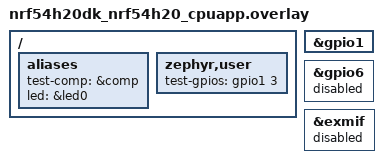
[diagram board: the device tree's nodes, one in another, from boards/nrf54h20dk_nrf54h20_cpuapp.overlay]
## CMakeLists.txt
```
#
# Copyright (c) 2024 Nordic Semiconductor ASA
#
# SPDX-License-Identifier: LicenseRef-Nordic-5-Clause
#

cmake_minimum_required(VERSION 3.20.0)

find_package(Zephyr REQUIRED HINTS $ENV{ZEPHYR_BASE})
if(NOT SYSBUILD)
  message(FATAL_ERROR
    " This is a multi-image application that should be built using sysbuild.\n"
    " Add --sysbuild argument to west build command to prepare all the images."
  )
endif()

project(idle_comp)

target_sources(app PRIVATE src/main.c)
```

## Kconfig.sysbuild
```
#
# Copyright (c) 2024 Nordic Semiconductor ASA
#
# SPDX-License-Identifier: LicenseRef-Nordic-5-Clause
#

choice NETCORE
	default NETCORE_REMOTE_SLEEP_FOREVER

config NETCORE_REMOTE_SLEEP_FOREVER
	bool "Remote sleep forever image"

endchoice

config NETCORE_IMAGE_NAME
	default "remote_sleep_forever" if NETCORE_REMOTE_SLEEP_FOREVER

config NETCORE_IMAGE_PATH
	default "$(ZEPHYR_NRF_MODULE_DIR)/tests/benchmarks/power_consumption/common/remote_sleep_forever" if NETCORE_REMOTE_SLEEP_FOREVER

source "share/sysbuild/Kconfig"
```

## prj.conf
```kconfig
CONFIG_COMPARATOR=y
CONFIG_GPIO=y

CONFIG_PM=y
CONFIG_PM_DEVICE=y
CONFIG_PM_DEVICE_RUNTIME=y
CONFIG_POWEROFF=y
CONFIG_BOOT_BANNER=n
CONFIG_NCS_BOOT_BANNER=n
CONFIG_ASSERT=y

# Enable for debugging purposes only
CONFIG_PRINTK=n
CONFIG_LOG=n
CONFIG_CONSOLE=n
CONFIG_UART_CONSOLE=n
CONFIG_SERIAL=n
```

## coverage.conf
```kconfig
CONFIG_COMPARATOR=y
CONFIG_GPIO=y

CONFIG_PM=y
CONFIG_PM_DEVICE=y
CONFIG_PM_DEVICE_RUNTIME=y
CONFIG_POWEROFF=y

CONFIG_BOOT_BANNER=n
CONFIG_NCS_BOOT_BANNER=n
CONFIG_ASSERT=n
CONFIG_CLOCK_CONTROL=n

CONFIG_PRINTK=y
CONFIG_LOG=n
CONFIG_CONSOLE=y
CONFIG_UART_CONSOLE=y

CONFIG_LOG_BUFFER_SIZE=16384
```

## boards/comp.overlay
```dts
/*
 * Copyright (c) 2024 Nordic Semiconductor ASA
 *
 * SPDX-License-Identifier: LicenseRef-Nordic-5-Clause
 */

#include <zephyr/dt-bindings/comparator/nrf-comp.h>

&comp {
	main-mode = "SE";
	psel = <NRF_COMP_AIN2>; /* P1.02 */
	refsel = "INT_1V2";
	sp-mode = "HIGH";
	th-up = <63>;
	th-down = <59>;
	isource = "DISABLED";
	status = "okay";
};
```

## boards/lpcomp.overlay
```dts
/*
 * Copyright (c) 2024 Nordic Semiconductor ASA
 *
 * SPDX-License-Identifier: LicenseRef-Nordic-5-Clause
 */

#include <zephyr/dt-bindings/comparator/nrf-comp.h>

&comp {
	compatible = "nordic,nrf-lpcomp";
	psel = <NRF_COMP_AIN2>; /* P1.02 */
	refsel = "VDD_4_8";
	status = "okay";
};
```

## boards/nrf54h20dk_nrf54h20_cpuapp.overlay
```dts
/*
 * Copyright (c) 2024 Nordic Semiconductor ASA
 *
 * SPDX-License-Identifier: LicenseRef-Nordic-5-Clause
 */

/ {
	aliases {
		test-comp = &comp;
		led = &led0;
		/delete-property/ led1;
	};

	zephyr,user {
		test-gpios = <&gpio1 3 GPIO_ACTIVE_HIGH>;
	};
};

/delete-node/ &led1;

&gpio1 {
	status = "okay";
};

&gpio6 {
	status = "disabled";
};

&exmif {
	status = "disabled";
};
```

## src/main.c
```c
/*
 * Copyright (c) 2024 Nordic Semiconductor ASA
 *
 * SPDX-License-Identifier: LicenseRef-Nordic-5-Clause
 */

#include <zephyr/drivers/comparator.h>
#include <zephyr/drivers/gpio.h>
#include <zephyr/kernel.h>
#include <zephyr/pm/device_runtime.h>

static const struct device *test_dev = DEVICE_DT_GET(DT_ALIAS(test_comp));
static const struct gpio_dt_spec test_pin = GPIO_DT_SPEC_GET(DT_PATH(zephyr_user), test_gpios);
static const struct gpio_dt_spec led = GPIO_DT_SPEC_GET(DT_ALIAS(led0), gpios);

volatile int counter;
static void test_callback(const struct device *dev, void *user_data)
{
	counter++;
}

int main(void)
{

	int rc;
	int test_repetitions = 3;

	gpio_pin_configure_dt(&test_pin, GPIO_OUTPUT_INACTIVE);

	rc = gpio_is_ready_dt(&led);
	__ASSERT(rc, "Error: GPIO Device not ready");

	rc = gpio_pin_configure_dt(&led, GPIO_OUTPUT_INACTIVE);
	__ASSERT(rc == 0, "Could not configure led GPIO");

	pm_device_runtime_get(test_dev);

	rc = comparator_set_trigger_callback(test_dev, test_callback, NULL);
	__ASSERT_NO_MSG(rc == 0);

	rc = comparator_set_trigger(test_dev, COMPARATOR_TRIGGER_BOTH_EDGES);
	__ASSERT_NO_MSG(rc == 0);

#if defined(CONFIG_COVERAGE)
	printk("Coverage analysis enabled\n");
	while (test_repetitions--)
#else
	while (test_repetitions)
#endif
	{
		counter = 0;
		k_busy_wait(200000);
		gpio_pin_set_dt(&test_pin, 1);
		k_busy_wait(400000);
		__ASSERT_NO_MSG(counter == 1);
		gpio_pin_set_dt(&test_pin, 0);
		k_busy_wait(400000);
		__ASSERT_NO_MSG(counter == 2);
		pm_device_runtime_put(test_dev);
		gpio_pin_set_dt(&led, 0);
		k_msleep(1000);
		gpio_pin_set_dt(&led, 1);
		pm_device_runtime_get(test_dev);
		k_msleep(1);
	}

#if defined(CONFIG_COVERAGE)
	printk("Coverage analysis start\n");
#endif
	return 0;
}
```
